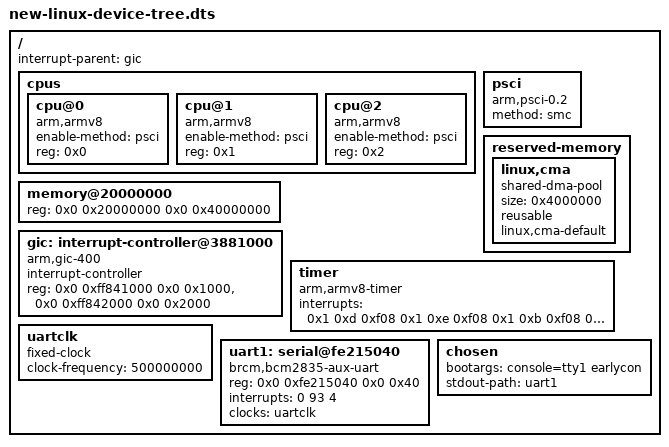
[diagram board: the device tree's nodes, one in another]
/dts-v1/;

/ {
	#address-cells = <2>;
	#size-cells = <2>;
	interrupt-parent = <&gic>;

	cpus {
		#size-cells = <0x0>;
		#address-cells = <0x1>;

		cpu@0 {
			compatible = "arm,armv8";
			device_type = "cpu";
			enable-method = "psci";
			reg = <0x0>;
		};

		cpu@1 {
			compatible = "arm,armv8";
			device_type = "cpu";
			enable-method = "psci";
			reg = <0x1>;
		};

		cpu@2 {
			compatible = "arm,armv8";
			device_type = "cpu";
			enable-method = "psci";
			reg = <0x2>;
		};

	};

	psci {
		compatible = "arm,psci-0.2";
		method = "smc";
	};

	memory@20000000 {
		reg = <0x0 0x20000000 0x0 0x40000000>;
		device_type = "memory";
	};

	reserved-memory {
		#address-cells = <0x02>;
		#size-cells = <0x01>;
		ranges;

		linux,cma {
			compatible = "shared-dma-pool";
			size = <0x4000000>;
			reusable;
			linux,cma-default;
		};
	};

	gic: interrupt-controller@3881000 {
		compatible = "arm,gic-400";
		#interrupt-cells = <3>;
		interrupt-controller;
		reg = <0x0 0xff841000 0x0 0x1000>,
		      <0x0 0xff842000 0x0 0x2000>;
	};

	timer {
		compatible = "arm,armv8-timer";
		interrupts = <0x1 0xd 0xf08 0x1 0xe 0xf08 0x1 0xb 0xf08 0x1 0xa 0xf08>;
	};

    uartclk: uartclk {
		compatible = "fixed-clock";
		#clock-cells = <0>;
		clock-frequency = <500000000>;
	};

	uart1: serial@fe215040 {
		compatible = "brcm,bcm2835-aux-uart";
		reg = <0x0 0xfe215040 0x0 0x40>;
		interrupts = <0 93 4>;
		clocks = <&uartclk>;
		status = "okay";
	};

	chosen {
		bootargs = "console=tty1 earlycon";
        stdout-path = <&uart1>;
	};

};
